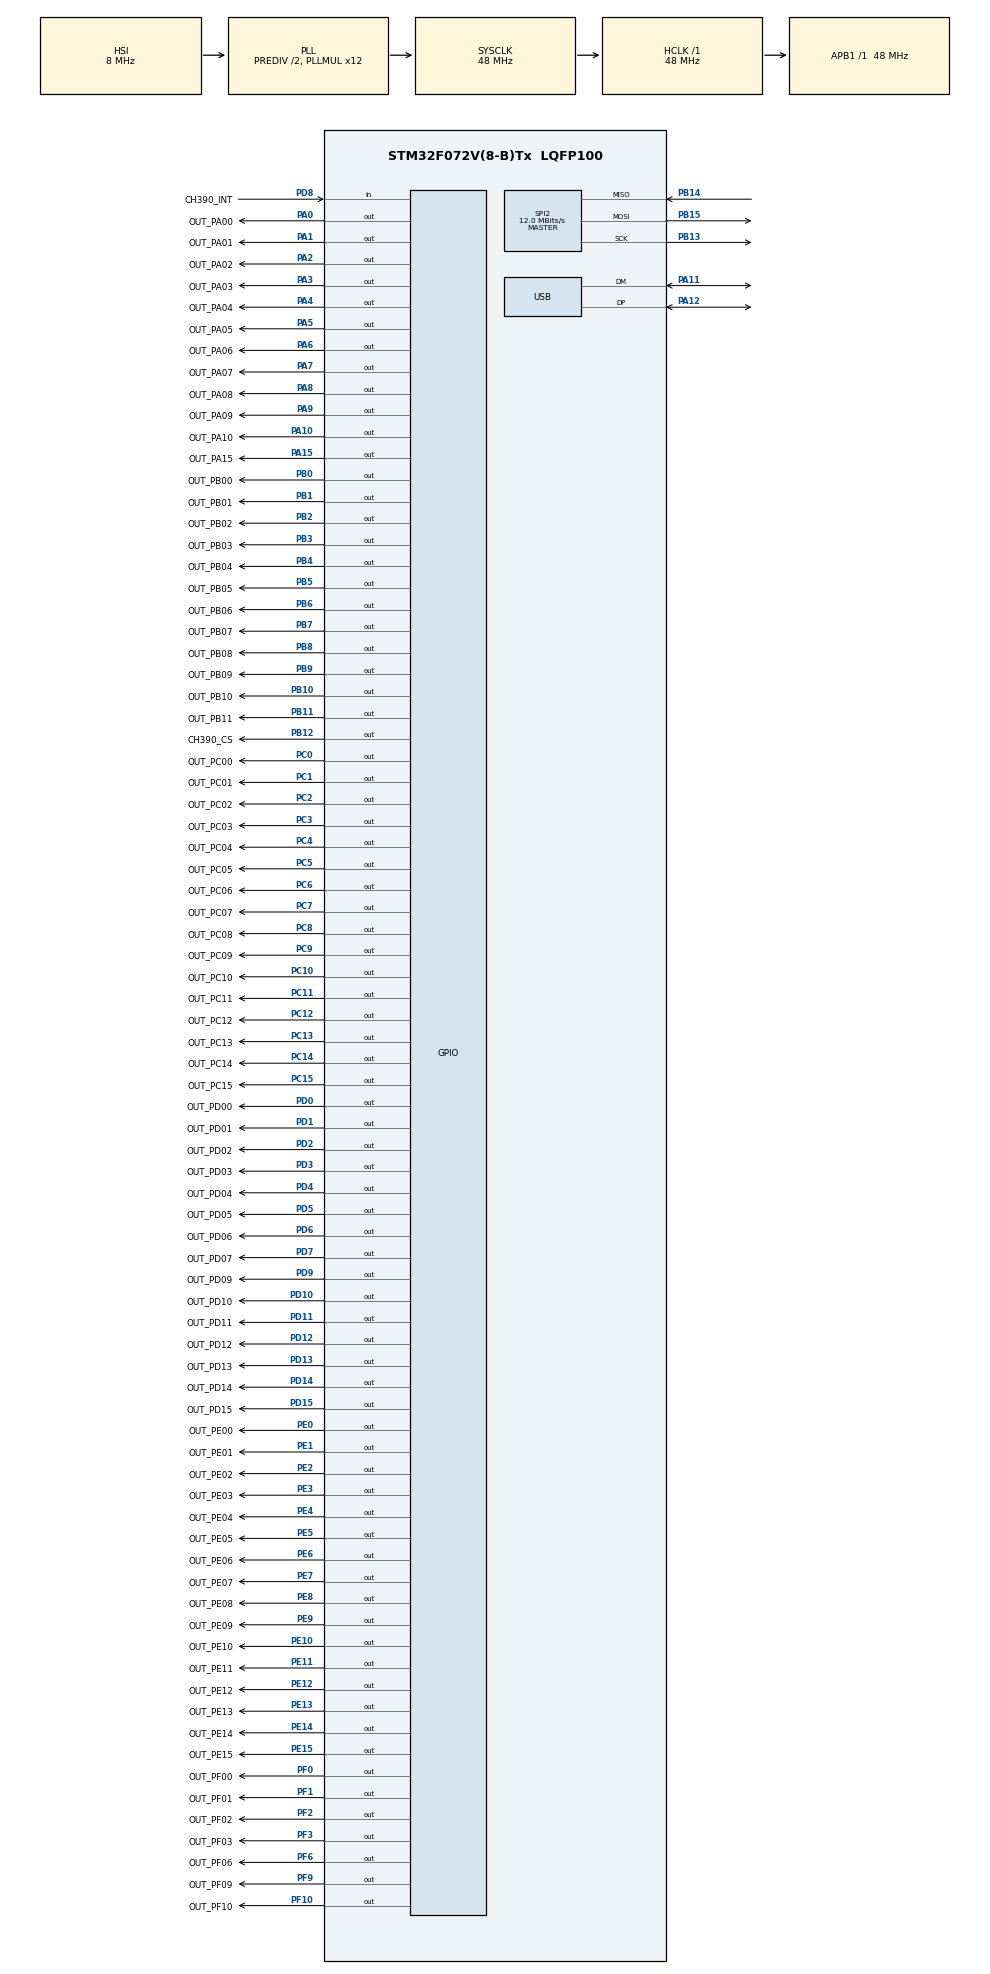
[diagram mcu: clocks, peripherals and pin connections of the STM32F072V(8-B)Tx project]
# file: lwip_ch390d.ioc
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Mcu.Family=STM32F0
Mcu.Name=STM32F072V(8-B)Tx
Mcu.Package=LQFP100
NVIC.USB_IRQn=true\:2\:0\:false\:false\:true\:true\:true\:true
PA0.GPIO_Label=OUT_PA00
PA0.GPIO_ModeDefaultOutputPP=GPIO_MODE_OUTPUT_PP
PA0.GPIO_PuPd=GPIO_NOPULL
PA0.GPIO_Speed=GPIO_SPEED_FREQ_LOW
PA0.PinState=GPIO_PIN_RESET
PA0.Signal=GPIO_Output
PA1.GPIO_Label=OUT_PA01
PA1.GPIO_ModeDefaultOutputPP=GPIO_MODE_OUTPUT_PP
PA1.GPIO_PuPd=GPIO_NOPULL
PA1.GPIO_Speed=GPIO_SPEED_FREQ_LOW
PA1.PinState=GPIO_PIN_RESET
PA1.Signal=GPIO_Output
PA10.GPIO_Label=OUT_PA10
PA10.GPIO_ModeDefaultOutputPP=GPIO_MODE_OUTPUT_PP
PA10.GPIO_PuPd=GPIO_NOPULL
PA10.GPIO_Speed=GPIO_SPEED_FREQ_LOW
PA10.PinState=GPIO_PIN_RESET
PA10.Signal=GPIO_Output
PA11.Mode=Device
PA11.Signal=USB_DM
PA12.Mode=Device
PA12.Signal=USB_DP
PA13.Mode=Serial_Wire
PA13.Signal=SYS_SWDIO
PA14.Mode=Serial_Wire
PA14.Signal=SYS_SWCLK
PA15.GPIO_Label=OUT_PA15
PA15.GPIO_ModeDefaultOutputPP=GPIO_MODE_OUTPUT_PP
PA15.GPIO_PuPd=GPIO_NOPULL
PA15.GPIO_Speed=GPIO_SPEED_FREQ_LOW
PA15.PinState=GPIO_PIN_RESET
PA15.Signal=GPIO_Output
PA2.GPIO_Label=OUT_PA02
PA2.GPIO_ModeDefaultOutputPP=GPIO_MODE_OUTPUT_PP
PA2.GPIO_PuPd=GPIO_NOPULL
PA2.GPIO_Speed=GPIO_SPEED_FREQ_LOW
PA2.PinState=GPIO_PIN_RESET
PA2.Signal=GPIO_Output
PA3.GPIO_Label=OUT_PA03
PA3.GPIO_ModeDefaultOutputPP=GPIO_MODE_OUTPUT_PP
PA3.GPIO_PuPd=GPIO_NOPULL
PA3.GPIO_Speed=GPIO_SPEED_FREQ_LOW
PA3.PinState=GPIO_PIN_RESET
PA3.Signal=GPIO_Output
PA4.GPIO_Label=OUT_PA04
PA4.GPIO_ModeDefaultOutputPP=GPIO_MODE_OUTPUT_PP
PA4.GPIO_PuPd=GPIO_NOPULL
PA4.GPIO_Speed=GPIO_SPEED_FREQ_LOW
PA4.PinState=GPIO_PIN_RESET
PA4.Signal=GPIO_Output
PA5.GPIO_Label=OUT_PA05
PA5.GPIO_ModeDefaultOutputPP=GPIO_MODE_OUTPUT_PP
PA5.GPIO_PuPd=GPIO_NOPULL
PA5.GPIO_Speed=GPIO_SPEED_FREQ_LOW
PA5.PinState=GPIO_PIN_RESET
PA5.Signal=GPIO_Output
PA6.GPIO_Label=OUT_PA06
PA6.GPIO_ModeDefaultOutputPP=GPIO_MODE_OUTPUT_PP
PA6.GPIO_PuPd=GPIO_NOPULL
PA6.GPIO_Speed=GPIO_SPEED_FREQ_LOW
PA6.PinState=GPIO_PIN_RESET
PA6.Signal=GPIO_Output
PA7.GPIO_Label=OUT_PA07
PA7.GPIO_ModeDefaultOutputPP=GPIO_MODE_OUTPUT_PP
PA7.GPIO_PuPd=GPIO_NOPULL
PA7.GPIO_Speed=GPIO_SPEED_FREQ_LOW
PA7.PinState=GPIO_PIN_RESET
PA7.Signal=GPIO_Output
PA8.GPIO_Label=OUT_PA08
PA8.GPIO_ModeDefaultOutputPP=GPIO_MODE_OUTPUT_PP
PA8.GPIO_PuPd=GPIO_NOPULL
PA8.GPIO_Speed=GPIO_SPEED_FREQ_LOW
PA8.PinState=GPIO_PIN_RESET
PA8.Signal=GPIO_Output
PA9.GPIO_Label=OUT_PA09
PA9.GPIO_ModeDefaultOutputPP=GPIO_MODE_OUTPUT_PP
PA9.GPIO_PuPd=GPIO_NOPULL
PA9.GPIO_Speed=GPIO_SPEED_FREQ_LOW
PA9.PinState=GPIO_PIN_RESET
PA9.Signal=GPIO_Output
PB0.GPIO_Label=OUT_PB00
PB0.GPIO_ModeDefaultOutputPP=GPIO_MODE_OUTPUT_PP
PB0.GPIO_PuPd=GPIO_NOPULL
PB0.GPIO_Speed=GPIO_SPEED_FREQ_LOW
PB0.PinState=GPIO_PIN_RESET
PB0.Signal=GPIO_Output
PB1.GPIO_Label=OUT_PB01
PB1.GPIO_ModeDefaultOutputPP=GPIO_MODE_OUTPUT_PP
PB1.GPIO_PuPd=GPIO_NOPULL
PB1.GPIO_Speed=GPIO_SPEED_FREQ_LOW
PB1.PinState=GPIO_PIN_RESET
PB1.Signal=GPIO_Output
PB10.GPIO_Label=OUT_PB10
PB10.GPIO_ModeDefaultOutputPP=GPIO_MODE_OUTPUT_PP
PB10.GPIO_PuPd=GPIO_NOPULL
PB10.GPIO_Speed=GPIO_SPEED_FREQ_LOW
PB10.PinState=GPIO_PIN_RESET
PB10.Signal=GPIO_Output
PB11.GPIO_Label=OUT_PB11
PB11.GPIO_ModeDefaultOutputPP=GPIO_MODE_OUTPUT_PP
PB11.GPIO_PuPd=GPIO_NOPULL
PB11.GPIO_Speed=GPIO_SPEED_FREQ_LOW
PB11.PinState=GPIO_PIN_RESET
PB11.Signal=GPIO_Output
PB12.GPIO_Label=CH390_CS
PB12.GPIO_ModeDefaultOutputPP=GPIO_MODE_OUTPUT_PP
PB12.GPIO_PuPd=GPIO_NOPULL
PB12.GPIO_Speed=GPIO_SPEED_FREQ_HIGH
PB12.PinState=GPIO_PIN_SET
PB12.Signal=GPIO_Output
PB13.GPIO_PuPd=GPIO_NOPULL
PB13.GPIO_Speed=GPIO_SPEED_FREQ_HIGH
PB13.Mode=Full_Duplex_Master
PB13.Signal=SPI2_SCK
PB14.GPIO_PuPd=GPIO_NOPULL
PB14.GPIO_Speed=GPIO_SPEED_FREQ_HIGH
PB14.Mode=Full_Duplex_Master
PB14.Signal=SPI2_MISO
PB15.GPIO_PuPd=GPIO_NOPULL
PB15.GPIO_Speed=GPIO_SPEED_FREQ_HIGH
PB15.Mode=Full_Duplex_Master
PB15.Signal=SPI2_MOSI
PB2.GPIO_Label=OUT_PB02
PB2.GPIO_ModeDefaultOutputPP=GPIO_MODE_OUTPUT_PP
PB2.GPIO_PuPd=GPIO_NOPULL
PB2.GPIO_Speed=GPIO_SPEED_FREQ_LOW
PB2.PinState=GPIO_PIN_RESET
PB2.Signal=GPIO_Output
PB3.GPIO_Label=OUT_PB03
PB3.GPIO_ModeDefaultOutputPP=GPIO_MODE_OUTPUT_PP
PB3.GPIO_PuPd=GPIO_NOPULL
PB3.GPIO_Speed=GPIO_SPEED_FREQ_LOW
PB3.PinState=GPIO_PIN_RESET
PB3.Signal=GPIO_Output
PB4.GPIO_Label=OUT_PB04
PB4.GPIO_ModeDefaultOutputPP=GPIO_MODE_OUTPUT_PP
PB4.GPIO_PuPd=GPIO_NOPULL
PB4.GPIO_Speed=GPIO_SPEED_FREQ_LOW
PB4.PinState=GPIO_PIN_RESET
PB4.Signal=GPIO_Output
PB5.GPIO_Label=OUT_PB05
PB5.GPIO_ModeDefaultOutputPP=GPIO_MODE_OUTPUT_PP
PB5.GPIO_PuPd=GPIO_NOPULL
PB5.GPIO_Speed=GPIO_SPEED_FREQ_LOW
PB5.PinState=GPIO_PIN_RESET
PB5.Signal=GPIO_Output
PB6.GPIO_Label=OUT_PB06
PB6.GPIO_ModeDefaultOutputPP=GPIO_MODE_OUTPUT_PP
PB6.GPIO_PuPd=GPIO_NOPULL
PB6.GPIO_Speed=GPIO_SPEED_FREQ_LOW
PB6.PinState=GPIO_PIN_RESET
PB6.Signal=GPIO_Output
PB7.GPIO_Label=OUT_PB07
PB7.GPIO_ModeDefaultOutputPP=GPIO_MODE_OUTPUT_PP
PB7.GPIO_PuPd=GPIO_NOPULL
PB7.GPIO_Speed=GPIO_SPEED_FREQ_LOW
PB7.PinState=GPIO_PIN_RESET
PB7.Signal=GPIO_Output
PB8.GPIO_Label=OUT_PB08
PB8.GPIO_ModeDefaultOutputPP=GPIO_MODE_OUTPUT_PP
PB8.GPIO_PuPd=GPIO_NOPULL
PB8.GPIO_Speed=GPIO_SPEED_FREQ_LOW
PB8.PinState=GPIO_PIN_RESET
PB8.Signal=GPIO_Output
PB9.GPIO_Label=OUT_PB09
PB9.GPIO_ModeDefaultOutputPP=GPIO_MODE_OUTPUT_PP
PB9.GPIO_PuPd=GPIO_NOPULL
PB9.GPIO_Speed=GPIO_SPEED_FREQ_LOW
PB9.PinState=GPIO_PIN_RESET
PB9.Signal=GPIO_Output
PC0.GPIO_Label=OUT_PC00
PC0.GPIO_ModeDefaultOutputPP=GPIO_MODE_OUTPUT_PP
PC0.GPIO_PuPd=GPIO_NOPULL
PC0.GPIO_Speed=GPIO_SPEED_FREQ_LOW
PC0.PinState=GPIO_PIN_RESET
PC0.Signal=GPIO_Output
PC1.GPIO_Label=OUT_PC01
PC1.GPIO_ModeDefaultOutputPP=GPIO_MODE_OUTPUT_PP
PC1.GPIO_PuPd=GPIO_NOPULL
PC1.GPIO_Speed=GPIO_SPEED_FREQ_LOW
PC1.PinState=GPIO_PIN_RESET
PC1.Signal=GPIO_Output
PC10.GPIO_Label=OUT_PC10
PC10.GPIO_ModeDefaultOutputPP=GPIO_MODE_OUTPUT_PP
PC10.GPIO_PuPd=GPIO_NOPULL
PC10.GPIO_Speed=GPIO_SPEED_FREQ_LOW
PC10.PinState=GPIO_PIN_RESET
PC10.Signal=GPIO_Output
PC11.GPIO_Label=OUT_PC11
PC11.GPIO_ModeDefaultOutputPP=GPIO_MODE_OUTPUT_PP
PC11.GPIO_PuPd=GPIO_NOPULL
PC11.GPIO_Speed=GPIO_SPEED_FREQ_LOW
PC11.PinState=GPIO_PIN_RESET
PC11.Signal=GPIO_Output
PC12.GPIO_Label=OUT_PC12
PC12.GPIO_ModeDefaultOutputPP=GPIO_MODE_OUTPUT_PP
PC12.GPIO_PuPd=GPIO_NOPULL
PC12.GPIO_Speed=GPIO_SPEED_FREQ_LOW
PC12.PinState=GPIO_PIN_RESET
PC12.Signal=GPIO_Output
PC13.GPIO_Label=OUT_PC13
PC13.GPIO_ModeDefaultOutputPP=GPIO_MODE_OUTPUT_PP
PC13.GPIO_PuPd=GPIO_NOPULL
PC13.GPIO_Speed=GPIO_SPEED_FREQ_LOW
PC13.PinState=GPIO_PIN_RESET
PC13.Signal=GPIO_Output
PC14-OSC32_IN.GPIO_Label=OUT_PC14
PC14-OSC32_IN.GPIO_ModeDefaultOutputPP=GPIO_MODE_OUTPUT_PP
PC14-OSC32_IN.GPIO_PuPd=GPIO_NOPULL
PC14-OSC32_IN.GPIO_Speed=GPIO_SPEED_FREQ_LOW
PC14-OSC32_IN.PinState=GPIO_PIN_RESET
PC14-OSC32_IN.Signal=GPIO_Output
PC15-OSC32_OUT.GPIO_Label=OUT_PC15
PC15-OSC32_OUT.GPIO_ModeDefaultOutputPP=GPIO_MODE_OUTPUT_PP
PC15-OSC32_OUT.GPIO_PuPd=GPIO_NOPULL
PC15-OSC32_OUT.GPIO_Speed=GPIO_SPEED_FREQ_LOW
PC15-OSC32_OUT.PinState=GPIO_PIN_RESET
PC15-OSC32_OUT.Signal=GPIO_Output
PC2.GPIO_Label=OUT_PC02
PC2.GPIO_ModeDefaultOutputPP=GPIO_MODE_OUTPUT_PP
PC2.GPIO_PuPd=GPIO_NOPULL
PC2.GPIO_Speed=GPIO_SPEED_FREQ_LOW
PC2.PinState=GPIO_PIN_RESET
PC2.Signal=GPIO_Output
PC3.GPIO_Label=OUT_PC03
PC3.GPIO_ModeDefaultOutputPP=GPIO_MODE_OUTPUT_PP
PC3.GPIO_PuPd=GPIO_NOPULL
PC3.GPIO_Speed=GPIO_SPEED_FREQ_LOW
PC3.PinState=GPIO_PIN_RESET
PC3.Signal=GPIO_Output
PC4.GPIO_Label=OUT_PC04
PC4.GPIO_ModeDefaultOutputPP=GPIO_MODE_OUTPUT_PP
PC4.GPIO_PuPd=GPIO_NOPULL
PC4.GPIO_Speed=GPIO_SPEED_FREQ_LOW
PC4.PinState=GPIO_PIN_RESET
PC4.Signal=GPIO_Output
PC5.GPIO_Label=OUT_PC05
PC5.GPIO_ModeDefaultOutputPP=GPIO_MODE_OUTPUT_PP
PC5.GPIO_PuPd=GPIO_NOPULL
PC5.GPIO_Speed=GPIO_SPEED_FREQ_LOW
PC5.PinState=GPIO_PIN_RESET
PC5.Signal=GPIO_Output
PC6.GPIO_Label=OUT_PC06
PC6.GPIO_ModeDefaultOutputPP=GPIO_MODE_OUTPUT_PP
PC6.GPIO_PuPd=GPIO_NOPULL
PC6.GPIO_Speed=GPIO_SPEED_FREQ_LOW
PC6.PinState=GPIO_PIN_RESET
PC6.Signal=GPIO_Output
PC7.GPIO_Label=OUT_PC07
PC7.GPIO_ModeDefaultOutputPP=GPIO_MODE_OUTPUT_PP
PC7.GPIO_PuPd=GPIO_NOPULL
PC7.GPIO_Speed=GPIO_SPEED_FREQ_LOW
PC7.PinState=GPIO_PIN_RESET
PC7.Signal=GPIO_Output
PC8.GPIO_Label=OUT_PC08
PC8.GPIO_ModeDefaultOutputPP=GPIO_MODE_OUTPUT_PP
PC8.GPIO_PuPd=GPIO_NOPULL
PC8.GPIO_Speed=GPIO_SPEED_FREQ_LOW
PC8.PinState=GPIO_PIN_RESET
PC8.Signal=GPIO_Output
PC9.GPIO_Label=OUT_PC09
PC9.GPIO_ModeDefaultOutputPP=GPIO_MODE_OUTPUT_PP
PC9.GPIO_PuPd=GPIO_NOPULL
PC9.GPIO_Speed=GPIO_SPEED_FREQ_LOW
PC9.PinState=GPIO_PIN_RESET
PC9.Signal=GPIO_Output
PD0.GPIO_Label=OUT_PD00
PD0.GPIO_ModeDefaultOutputPP=GPIO_MODE_OUTPUT_PP
PD0.GPIO_PuPd=GPIO_NOPULL
PD0.GPIO_Speed=GPIO_SPEED_FREQ_LOW
PD0.PinState=GPIO_PIN_RESET
PD0.Signal=GPIO_Output
PD1.GPIO_Label=OUT_PD01
PD1.GPIO_ModeDefaultOutputPP=GPIO_MODE_OUTPUT_PP
PD1.GPIO_PuPd=GPIO_NOPULL
PD1.GPIO_Speed=GPIO_SPEED_FREQ_LOW
PD1.PinState=GPIO_PIN_RESET
PD1.Signal=GPIO_Output
PD10.GPIO_Label=OUT_PD10
PD10.GPIO_ModeDefaultOutputPP=GPIO_MODE_OUTPUT_PP
PD10.GPIO_PuPd=GPIO_NOPULL
PD10.GPIO_Speed=GPIO_SPEED_FREQ_LOW
PD10.PinState=GPIO_PIN_RESET
PD10.Signal=GPIO_Output
PD11.GPIO_Label=OUT_PD11
PD11.GPIO_ModeDefaultOutputPP=GPIO_MODE_OUTPUT_PP
PD11.GPIO_PuPd=GPIO_NOPULL
PD11.GPIO_Speed=GPIO_SPEED_FREQ_LOW
PD11.PinState=GPIO_PIN_RESET
PD11.Signal=GPIO_Output
PD12.GPIO_Label=OUT_PD12
PD12.GPIO_ModeDefaultOutputPP=GPIO_MODE_OUTPUT_PP
PD12.GPIO_PuPd=GPIO_NOPULL
PD12.GPIO_Speed=GPIO_SPEED_FREQ_LOW
PD12.PinState=GPIO_PIN_RESET
PD12.Signal=GPIO_Output
PD13.GPIO_Label=OUT_PD13
PD13.GPIO_ModeDefaultOutputPP=GPIO_MODE_OUTPUT_PP
PD13.GPIO_PuPd=GPIO_NOPULL
PD13.GPIO_Speed=GPIO_SPEED_FREQ_LOW
PD13.PinState=GPIO_PIN_RESET
PD13.Signal=GPIO_Output
PD14.GPIO_Label=OUT_PD14
PD14.GPIO_ModeDefaultOutputPP=GPIO_MODE_OUTPUT_PP
PD14.GPIO_PuPd=GPIO_NOPULL
PD14.GPIO_Speed=GPIO_SPEED_FREQ_LOW
PD14.PinState=GPIO_PIN_RESET
PD14.Signal=GPIO_Output
PD15.GPIO_Label=OUT_PD15
PD15.GPIO_ModeDefaultOutputPP=GPIO_MODE_OUTPUT_PP
PD15.GPIO_PuPd=GPIO_NOPULL
PD15.GPIO_Speed=GPIO_SPEED_FREQ_LOW
PD15.PinState=GPIO_PIN_RESET
PD15.Signal=GPIO_Output
PD2.GPIO_Label=OUT_PD02
PD2.GPIO_ModeDefaultOutputPP=GPIO_MODE_OUTPUT_PP
PD2.GPIO_PuPd=GPIO_NOPULL
PD2.GPIO_Speed=GPIO_SPEED_FREQ_LOW
PD2.PinState=GPIO_PIN_RESET
PD2.Signal=GPIO_Output
PD3.GPIO_Label=OUT_PD03
PD3.GPIO_ModeDefaultOutputPP=GPIO_MODE_OUTPUT_PP
PD3.GPIO_PuPd=GPIO_NOPULL
PD3.GPIO_Speed=GPIO_SPEED_FREQ_LOW
PD3.PinState=GPIO_PIN_RESET
PD3.Signal=GPIO_Output
PD4.GPIO_Label=OUT_PD04
PD4.GPIO_ModeDefaultOutputPP=GPIO_MODE_OUTPUT_PP
PD4.GPIO_PuPd=GPIO_NOPULL
PD4.GPIO_Speed=GPIO_SPEED_FREQ_LOW
PD4.PinState=GPIO_PIN_RESET
PD4.Signal=GPIO_Output
PD5.GPIO_Label=OUT_PD05
PD5.GPIO_ModeDefaultOutputPP=GPIO_MODE_OUTPUT_PP
PD5.GPIO_PuPd=GPIO_NOPULL
PD5.GPIO_Speed=GPIO_SPEED_FREQ_LOW
PD5.PinState=GPIO_PIN_RESET
PD5.Signal=GPIO_Output
PD6.GPIO_Label=OUT_PD06
PD6.GPIO_ModeDefaultOutputPP=GPIO_MODE_OUTPUT_PP
PD6.GPIO_PuPd=GPIO_NOPULL
PD6.GPIO_Speed=GPIO_SPEED_FREQ_LOW
PD6.PinState=GPIO_PIN_RESET
PD6.Signal=GPIO_Output
PD7.GPIO_Label=OUT_PD07
PD7.GPIO_ModeDefaultOutputPP=GPIO_MODE_OUTPUT_PP
PD7.GPIO_PuPd=GPIO_NOPULL
PD7.GPIO_Speed=GPIO_SPEED_FREQ_LOW
PD7.PinState=GPIO_PIN_RESET
PD7.Signal=GPIO_Output
PD8.GPIO_Label=CH390_INT
PD8.GPIO_PuPd=GPIO_PULLDOWN
PD8.Signal=GPIO_Input
PD9.GPIO_Label=OUT_PD09
PD9.GPIO_ModeDefaultOutputPP=GPIO_MODE_OUTPUT_PP
PD9.GPIO_PuPd=GPIO_NOPULL
PD9.GPIO_Speed=GPIO_SPEED_FREQ_LOW
PD9.PinState=GPIO_PIN_RESET
PD9.Signal=GPIO_Output
PE0.GPIO_Label=OUT_PE00
PE0.GPIO_ModeDefaultOutputPP=GPIO_MODE_OUTPUT_PP
PE0.GPIO_PuPd=GPIO_NOPULL
PE0.GPIO_Speed=GPIO_SPEED_FREQ_LOW
PE0.PinState=GPIO_PIN_RESET
PE0.Signal=GPIO_Output
PE1.GPIO_Label=OUT_PE01
PE1.GPIO_ModeDefaultOutputPP=GPIO_MODE_OUTPUT_PP
PE1.GPIO_PuPd=GPIO_NOPULL
PE1.GPIO_Speed=GPIO_SPEED_FREQ_LOW
PE1.PinState=GPIO_PIN_RESET
PE1.Signal=GPIO_Output
PE10.GPIO_Label=OUT_PE10
PE10.GPIO_ModeDefaultOutputPP=GPIO_MODE_OUTPUT_PP
PE10.GPIO_PuPd=GPIO_NOPULL
PE10.GPIO_Speed=GPIO_SPEED_FREQ_LOW
PE10.PinState=GPIO_PIN_RESET
PE10.Signal=GPIO_Output
PE11.GPIO_Label=OUT_PE11
PE11.GPIO_ModeDefaultOutputPP=GPIO_MODE_OUTPUT_PP
PE11.GPIO_PuPd=GPIO_NOPULL
PE11.GPIO_Speed=GPIO_SPEED_FREQ_LOW
PE11.PinState=GPIO_PIN_RESET
PE11.Signal=GPIO_Output
PE12.GPIO_Label=OUT_PE12
PE12.GPIO_ModeDefaultOutputPP=GPIO_MODE_OUTPUT_PP
PE12.GPIO_PuPd=GPIO_NOPULL
PE12.GPIO_Speed=GPIO_SPEED_FREQ_LOW
PE12.PinState=GPIO_PIN_RESET
PE12.Signal=GPIO_Output
PE13.GPIO_Label=OUT_PE13
PE13.GPIO_ModeDefaultOutputPP=GPIO_MODE_OUTPUT_PP
PE13.GPIO_PuPd=GPIO_NOPULL
PE13.GPIO_Speed=GPIO_SPEED_FREQ_LOW
PE13.PinState=GPIO_PIN_RESET
PE13.Signal=GPIO_Output
PE14.GPIO_Label=OUT_PE14
PE14.GPIO_ModeDefaultOutputPP=GPIO_MODE_OUTPUT_PP
PE14.GPIO_PuPd=GPIO_NOPULL
PE14.GPIO_Speed=GPIO_SPEED_FREQ_LOW
PE14.PinState=GPIO_PIN_RESET
PE14.Signal=GPIO_Output
PE15.GPIO_Label=OUT_PE15
PE15.GPIO_ModeDefaultOutputPP=GPIO_MODE_OUTPUT_PP
PE15.GPIO_PuPd=GPIO_NOPULL
PE15.GPIO_Speed=GPIO_SPEED_FREQ_LOW
PE15.PinState=GPIO_PIN_RESET
PE15.Signal=GPIO_Output
PE2.GPIO_Label=OUT_PE02
PE2.GPIO_ModeDefaultOutputPP=GPIO_MODE_OUTPUT_PP
PE2.GPIO_PuPd=GPIO_NOPULL
PE2.GPIO_Speed=GPIO_SPEED_FREQ_LOW
PE2.PinState=GPIO_PIN_RESET
PE2.Signal=GPIO_Output
PE3.GPIO_Label=OUT_PE03
PE3.GPIO_ModeDefaultOutputPP=GPIO_MODE_OUTPUT_PP
PE3.GPIO_PuPd=GPIO_NOPULL
PE3.GPIO_Speed=GPIO_SPEED_FREQ_LOW
PE3.PinState=GPIO_PIN_RESET
PE3.Signal=GPIO_Output
PE4.GPIO_Label=OUT_PE04
PE4.GPIO_ModeDefaultOutputPP=GPIO_MODE_OUTPUT_PP
PE4.GPIO_PuPd=GPIO_NOPULL
PE4.GPIO_Speed=GPIO_SPEED_FREQ_LOW
PE4.PinState=GPIO_PIN_RESET
PE4.Signal=GPIO_Output
PE5.GPIO_Label=OUT_PE05
PE5.GPIO_ModeDefaultOutputPP=GPIO_MODE_OUTPUT_PP
PE5.GPIO_PuPd=GPIO_NOPULL
PE5.GPIO_Speed=GPIO_SPEED_FREQ_LOW
PE5.PinState=GPIO_PIN_RESET
PE5.Signal=GPIO_Output
PE6.GPIO_Label=OUT_PE06
PE6.GPIO_ModeDefaultOutputPP=GPIO_MODE_OUTPUT_PP
PE6.GPIO_PuPd=GPIO_NOPULL
PE6.GPIO_Speed=GPIO_SPEED_FREQ_LOW
PE6.PinState=GPIO_PIN_RESET
PE6.Signal=GPIO_Output
PE7.GPIO_Label=OUT_PE07
PE7.GPIO_ModeDefaultOutputPP=GPIO_MODE_OUTPUT_PP
PE7.GPIO_PuPd=GPIO_NOPULL
PE7.GPIO_Speed=GPIO_SPEED_FREQ_LOW
PE7.PinState=GPIO_PIN_RESET
PE7.Signal=GPIO_Output
PE8.GPIO_Label=OUT_PE08
PE8.GPIO_ModeDefaultOutputPP=GPIO_MODE_OUTPUT_PP
PE8.GPIO_PuPd=GPIO_NOPULL
PE8.GPIO_Speed=GPIO_SPEED_FREQ_LOW
PE8.PinState=GPIO_PIN_RESET
PE8.Signal=GPIO_Output
PE9.GPIO_Label=OUT_PE09
PE9.GPIO_ModeDefaultOutputPP=GPIO_MODE_OUTPUT_PP
PE9.GPIO_PuPd=GPIO_NOPULL
PE9.GPIO_Speed=GPIO_SPEED_FREQ_LOW
PE9.PinState=GPIO_PIN_RESET
PE9.Signal=GPIO_Output
PF0-OSC_IN.GPIO_Label=OUT_PF00
PF0-OSC_IN.GPIO_ModeDefaultOutputPP=GPIO_MODE_OUTPUT_PP
PF0-OSC_IN.GPIO_PuPd=GPIO_NOPULL
PF0-OSC_IN.GPIO_Speed=GPIO_SPEED_FREQ_LOW
PF0-OSC_IN.PinState=GPIO_PIN_RESET
PF0-OSC_IN.Signal=GPIO_Output
PF1-OSC_OUT.GPIO_Label=OUT_PF01
PF1-OSC_OUT.GPIO_ModeDefaultOutputPP=GPIO_MODE_OUTPUT_PP
PF1-OSC_OUT.GPIO_PuPd=GPIO_NOPULL
PF1-OSC_OUT.GPIO_Speed=GPIO_SPEED_FREQ_LOW
PF1-OSC_OUT.PinState=GPIO_PIN_RESET
PF1-OSC_OUT.Signal=GPIO_Output
PF10.GPIO_Label=OUT_PF10
PF10.GPIO_ModeDefaultOutputPP=GPIO_MODE_OUTPUT_PP
PF10.GPIO_PuPd=GPIO_NOPULL
PF10.GPIO_Speed=GPIO_SPEED_FREQ_LOW
PF10.PinState=GPIO_PIN_RESET
PF10.Signal=GPIO_Output
PF2.GPIO_Label=OUT_PF02
PF2.GPIO_ModeDefaultOutputPP=GPIO_MODE_OUTPUT_PP
PF2.GPIO_PuPd=GPIO_NOPULL
PF2.GPIO_Speed=GPIO_SPEED_FREQ_LOW
PF2.PinState=GPIO_PIN_RESET
PF2.Signal=GPIO_Output
PF3.GPIO_Label=OUT_PF03
PF3.GPIO_ModeDefaultOutputPP=GPIO_MODE_OUTPUT_PP
PF3.GPIO_PuPd=GPIO_NOPULL
PF3.GPIO_Speed=GPIO_SPEED_FREQ_LOW
PF3.PinState=GPIO_PIN_RESET
PF3.Signal=GPIO_Output
PF6.GPIO_Label=OUT_PF06
PF6.GPIO_ModeDefaultOutputPP=GPIO_MODE_OUTPUT_PP
PF6.GPIO_PuPd=GPIO_NOPULL
PF6.GPIO_Speed=GPIO_SPEED_FREQ_LOW
PF6.PinState=GPIO_PIN_RESET
PF6.Signal=GPIO_Output
PF9.GPIO_Label=OUT_PF09
PF9.GPIO_ModeDefaultOutputPP=GPIO_MODE_OUTPUT_PP
PF9.GPIO_PuPd=GPIO_NOPULL
PF9.GPIO_Speed=GPIO_SPEED_FREQ_LOW
PF9.PinState=GPIO_PIN_RESET
PF9.Signal=GPIO_Output
ProjectManager.HeapSize=0x200
ProjectManager.StackSize=0x800
ProjectManager.TargetToolchain=MDK-ARM V5
RCC.AHBCLKDivider=RCC_SYSCLK_DIV1
RCC.AHBFreq_Value=48000000
RCC.APB1CLKDivider=RCC_HCLK_DIV1
RCC.APB1Freq_Value=48000000
RCC.APB1TimFreq_Value=48000000
RCC.ErrorLimitValue=34
RCC.HCLKFreq_Value=48000000
RCC.HSE_VALUE=8000000
RCC.HSI48CalibrationValue=32
RCC.HSI48_VALUE=48000000
RCC.HSI_VALUE=8000000
RCC.LSE_VALUE=32768
RCC.PLLDivider=RCC_PREDIV_DIV2
RCC.PLLMUL=RCC_PLL_MUL12
RCC.PLLSourceVirtual=RCC_PLLSOURCE_HSI
RCC.Polarity=RCC_CRS_SYNC_POLARITY_RISING
RCC.Prescaler=RCC_CRS_SYNC_DIV1
RCC.RTCClockSelection=RCC_RTCCLKSOURCE_LSI
RCC.ReloadValue=47999
RCC.ReloadValueType=UserValue
RCC.SYSCLKFreq_VALUE=48000000
RCC.SYSCLKSource=RCC_SYSCLKSOURCE_PLLCLK
RCC.USBClockSelection=RCC_USBCLKSOURCE_HSI48
RCC.USBFreq_Value=48000000
RTC.AsynchPrediv=124
RTC.HourFormat=RTC_HOURFORMAT_24
RTC.SynchPrediv=319
SPI2.BaudRatePrescaler=SPI_BAUDRATEPRESCALER_4
SPI2.CLKPhase=SPI_PHASE_2EDGE
SPI2.CLKPolarity=SPI_POLARITY_HIGH
SPI2.CRCCalculation=SPI_CRCCALCULATION_DISABLE
SPI2.CalculateBaudRate=12.0 MBits/s
SPI2.DataSize=SPI_DATASIZE_8BIT
SPI2.Direction=SPI_DIRECTION_2LINES
SPI2.FirstBit=SPI_FIRSTBIT_MSB
SPI2.Mode=SPI_MODE_MASTER
SPI2.NSS=SPI_NSS_SOFT
SPI2.TIMode=SPI_TIMODE_DISABLE
SPI2.VirtualType=VM_MASTER
USB.VirtualMode=Device
USB.battery_charging_enable=DISABLE
USB.low_power_enable=DISABLE
USB.lpm_enable=DISABLE
USB_DEVICE.APP_RX_DATA_SIZE=128
USB_DEVICE.APP_TX_DATA_SIZE=128
USB_DEVICE.CLASS_NAME_FS=CDC
USB_DEVICE.USBD_LPM_ENABLED=0
USB_DEVICE.VirtualMode=Cdc
USB_DEVICE.VirtualModeFS=Cdc_FS
VP_RCC_USB.Mode=CRS SYNC Source USB
VP_RTC_VS_RTC_Activate.Mode=RTC_Enabled
VP_RTC_VS_RTC_Calendar.Mode=RTC_Calendar
VP_USB_DEVICE_VS_USB_DEVICE_CDC_FS.Mode=CDC_FS
board=custom

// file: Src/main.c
/* USER CODE BEGIN Header */
/**
  ******************************************************************************
  * @file           : main.c
  * @brief          : Main program body
  ******************************************************************************
  * @attention
  *
  * Copyright (c) 2026 STMicroelectronics.
  * All rights reserved.
  *
  * This software is licensed under terms that can be found in the LICENSE file
  * in the root directory of this software component.
  * If no LICENSE file comes with this software, it is provided AS-IS.
  *
  ******************************************************************************
  */
/* USER CODE END Header */
#include "main.h"
#include "rtc.h"
#include "spi.h"
#include "usb_device.h"
#include "gpio.h"

/* USER CODE BEGIN Includes */
#include "network_app.h"
#include <stdio.h>
/* USER CODE END Includes */

void SystemClock_Config(void);

int main(void)
{

  /* MCU Configuration--------------------------------------------------------*/

  /* Reset of all peripherals, Initializes the Flash interface and the Systick. */
  HAL_Init();
  HAL_Delay(500);

  /* Configure the system clock */
  SystemClock_Config();

  /* Initialize all configured peripherals */
  MX_GPIO_Init();
  MX_SPI2_Init();
  MX_RTC_Init();
  MX_USB_DEVICE_Init();
  /* USER CODE BEGIN 2 */
  network_app_init();
  printf("main loop start\r\n");
  /* USER CODE END 2 */

  /* Infinite loop */
  while (1)
  {

    /* USER CODE BEGIN 3 */
    network_app_poll();
  }
  /* USER CODE END 3 */
}

void SystemClock_Config(void)
{
  RCC_OscInitTypeDef RCC_OscInitStruct = {0};
  RCC_ClkInitTypeDef RCC_ClkInitStruct = {0};
  RCC_PeriphCLKInitTypeDef PeriphClkInit = {0};
  RCC_CRSInitTypeDef RCC_CRSInitStruct = {0};

  /** Initializes the RCC Oscillators according to the specified parameters
  * in the RCC_OscInitTypeDef structure.
  */
  RCC_OscInitStruct.OscillatorType = RCC_OSCILLATORTYPE_HSI|RCC_OSCILLATORTYPE_HSI48
                              |RCC_OSCILLATORTYPE_LSI;
  RCC_OscInitStruct.HSIState = RCC_HSI_ON;
  RCC_OscInitStruct.HSI48State = RCC_HSI48_ON;
  RCC_OscInitStruct.HSICalibrationValue = RCC_HSICALIBRATION_DEFAULT;
  RCC_OscInitStruct.LSIState = RCC_LSI_ON;
  RCC_OscInitStruct.PLL.PLLState = RCC_PLL_ON;
  RCC_OscInitStruct.PLL.PLLSource = RCC_PLLSOURCE_HSI;
  RCC_OscInitStruct.PLL.PLLMUL = RCC_PLL_MUL12;
  RCC_OscInitStruct.PLL.PREDIV = RCC_PREDIV_DIV2;
  if (HAL_RCC_OscConfig(&RCC_OscInitStruct) != HAL_OK)
  {
    Error_Handler();
  }

  /** Initializes the CPU, AHB and APB buses clocks
  */
  RCC_ClkInitStruct.ClockType = RCC_CLOCKTYPE_HCLK|RCC_CLOCKTYPE_SYSCLK
                              |RCC_CLOCKTYPE_PCLK1;
  RCC_ClkInitStruct.SYSCLKSource = RCC_SYSCLKSOURCE_PLLCLK;
  RCC_ClkInitStruct.AHBCLKDivider = RCC_SYSCLK_DIV1;
  RCC_ClkInitStruct.APB1CLKDivider = RCC_HCLK_DIV1;

  if (HAL_RCC_ClockConfig(&RCC_ClkInitStruct, FLASH_LATENCY_1) != HAL_OK)
  {
    Error_Handler();
  }
  PeriphClkInit.PeriphClockSelection = RCC_PERIPHCLK_USB|RCC_PERIPHCLK_RTC;
  PeriphClkInit.RTCClockSelection = RCC_RTCCLKSOURCE_LSI;
  PeriphClkInit.UsbClockSelection = RCC_USBCLKSOURCE_HSI48;

  if (HAL_RCCEx_PeriphCLKConfig(&PeriphClkInit) != HAL_OK)
  {
    Error_Handler();
  }

  /** Enable the SYSCFG APB clock
  */
  __HAL_RCC_CRS_CLK_ENABLE();

  /** Configures CRS
  */
  RCC_CRSInitStruct.Prescaler = RCC_CRS_SYNC_DIV1;
  RCC_CRSInitStruct.Source = RCC_CRS_SYNC_SOURCE_USB;
  RCC_CRSInitStruct.Polarity = RCC_CRS_SYNC_POLARITY_RISING;
  RCC_CRSInitStruct.ReloadValue = 47999;
  RCC_CRSInitStruct.ErrorLimitValue = 34;
  RCC_CRSInitStruct.HSI48CalibrationValue = 32;

  HAL_RCCEx_CRSConfig(&RCC_CRSInitStruct);
}

void Error_Handler(void)
{
  __disable_irq();
  while (1)
  {
  }
}
